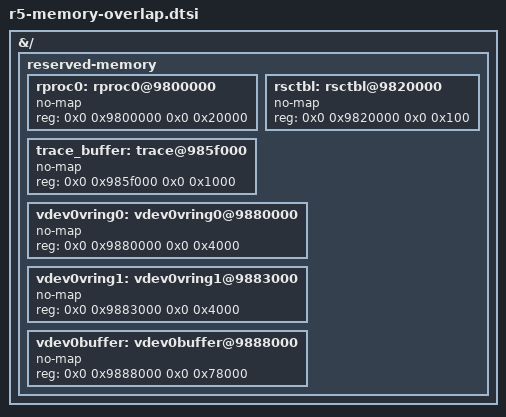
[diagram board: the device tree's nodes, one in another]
/* Fault: the second ring starts 0x1000 before the end of the first. The regions and addresses are those of core 0 in the
   pre-generated Linux device tree of the versal-vek280-multidomain machine of EDF 26.11 (meta-amd-adaptive-socs).
   Replace them with the product's memory map. */
&{/} {
	reserved-memory {
		#address-cells = <2>;
		#size-cells = <2>;
		ranges;
		rproc0: rproc0@9800000 {
			no-map;
			reg = <0x0 0x9800000 0x0 0x20000>;
		};
		rsctbl: rsctbl@9820000 {
			no-map;
			reg = <0x0 0x9820000 0x0 0x100>;
		};
		trace_buffer: trace@985f000 {
			no-map;
			reg = <0x0 0x985f000 0x0 0x1000>;
		};
		vdev0vring0: vdev0vring0@9880000 {
			no-map;
			reg = <0x0 0x9880000 0x0 0x4000>;
		};
		vdev0vring1: vdev0vring1@9883000 {
			no-map;
			reg = <0x0 0x9883000 0x0 0x4000>;
		};
		vdev0buffer: vdev0buffer@9888000 {
			no-map;
			reg = <0x0 0x9888000 0x0 0x78000>;
		};
	};
};
